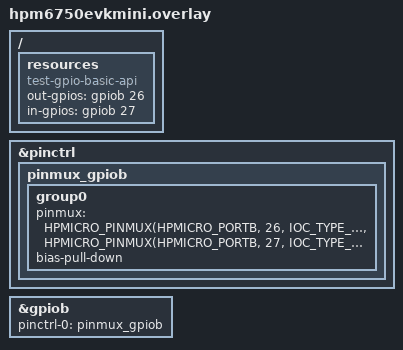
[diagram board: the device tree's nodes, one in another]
/*
 * Copyright (c) 2022 HPMicro
 * SPDX-License-Identifier: Apache-2.0
 */

 / {
	resources {
		compatible = "test-gpio-basic-api";
		out-gpios = <&gpiob 26 0>; /* P1 pin 32 (PB26) */
		in-gpios = <&gpiob 27 0>; /* P1 pin 29 (PB27) */
	};
};

&pinctrl {
	pinmux_gpiob: pinmux_gpiob {
		group0 {
			pinmux = <HPMICRO_PINMUX(HPMICRO_PORTB, 26, IOC_TYPE_IOC, 0, 0)>,
					 <HPMICRO_PINMUX(HPMICRO_PORTB, 27, IOC_TYPE_IOC, 0, 0)>;
					 bias-pull-down;
		};
	};
};

&gpiob {
	pinctrl-0 = <&pinmux_gpiob>;
	pinctrl-names = "default";
	status = "okay";
};
